VERSION "7166CEM CW V1.5"

NS_ :

BS_:

BU_: AI MCU VCU

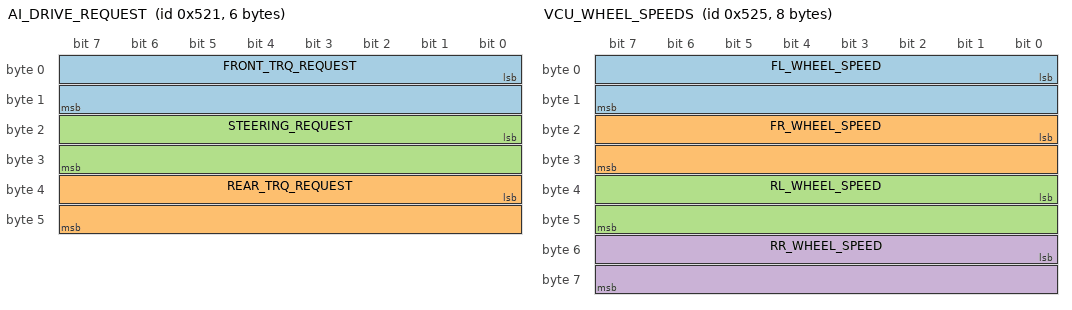
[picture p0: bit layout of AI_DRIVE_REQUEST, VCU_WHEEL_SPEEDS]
BO_ 1313 AI_DRIVE_REQUEST: 6 AI
 SG_ FRONT_TRQ_REQUEST : 0|16@1- (1,0) [-32768|32767] "Nm" Vector__XXX
 SG_ REAR_TRQ_REQUEST : 32|16@1- (1,0) [-32768|32767] "Nm" Vector__XXX
 SG_ STEERING_REQUEST : 16|16@1- (0.01,0) [-0.35|0.35] "rad" Vector__XXX

BO_ 1317 VCU_WHEEL_SPEEDS: 8 VCU
 SG_ FL_WHEEL_SPEED : 0|16@1+ (0.1,0) [0|65535] "rpm" Vector__XXX
 SG_ FR_WHEEL_SPEED : 16|16@1+ (0.1,0) [0|65535] "rpm" Vector__XXX
 SG_ RL_WHEEL_SPEED : 32|16@1+ (0.1,0) [0|65535] "rpm" Vector__XXX
 SG_ RR_WHEEL_SPEED : 48|16@1+ (0.1,0) [0|65535] "rpm" Vector__XXX

BO_ 1318 VCU_BATTERY: 2 VCU
 SG_ VOLTAGE : 0|16@1+ (0.001,0) [0|13] "V" Vector__XXX

BO_ 800 MOTOR_CURRENT: 4 MCU
 SG_ FRONT_CURRENT : 0|16@1- (1,0) [-30000|30000] "mA" Vector__XXX
 SG_ REAR_CURRENT : 16|16@1- (1,0) [-30000|30000] "mA" Vector__XXX
